# nrf7140_ml register map
Vendor: Nordic Semiconductor; Series: nRF71; File version: 1
Registers are 32-bit, read-write, reset 0x0 unless marked. A register's access mark holds for its fields unless they carry their own. Offsets are from the block's base; [hi:lo] are bit positions; lines under a group give offsets from that group; {n}, {i} and the like mark numbered series.

## GLOBAL_PCGCM300 — PCGC Master 0
Base 0x4900F000
Same registers: GLOBAL_PCGCM310 0x4901F000, PCGCM000 0x4A00F000, PCGCM010 0x4A01F000
{0xE0+4i} SETPWRCONTHRESHOLDBASE[{i}] (i=0..2) — Description collection: Set power consumption threshold base for power source / regulator n
  [3:0] SETPWRCONTHRESHOLDBASE
0xC00 UNLOCKBACKDOORS
  [15:0] UNLOCKBACKDOORS — Write: 0x00009375 to lock/unlock backdoors Read: 0x00000001 if backdoors is enabled Read: 0x00000000 if backdoors is disabled
0xC04 ENABLEPOWERREGFORCE
  [2:0] ENABLEPOWERREGFORCE
0xC08 POWERREGFORCE — Force reg
  [2:0] POWERREGFORCEREG
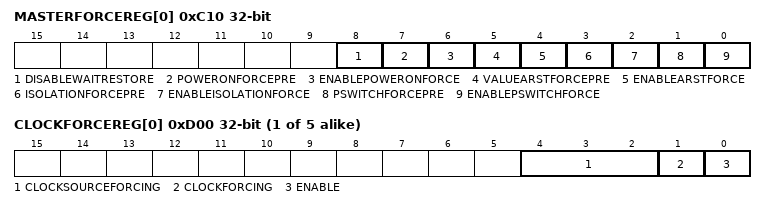
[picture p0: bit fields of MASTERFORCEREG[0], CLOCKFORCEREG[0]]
{0xC10+4i} MASTERFORCEREG[{i}] (i=0..0) — Description collection: Force reg
  [8] DISABLEWAITRESTORE — Turn off waiting for arst deactivation before retention restore
    1=Disable (Turn off waiting for arst deactivation before retention restore); 0=Enable (Wait for arst deactivation before retention restore)
  [7] POWERONFORCEPRE
  [6] ENABLEPOWERONFORCE
  [5] VALUEARSTFORCEPRE
  [4] ENABLEARSTFORCE
  [3] ISOLATIONFORCEPRE
  [2] ENABLEISOLATIONFORCE
  [1] PSWITCHFORCEPRE
  [0] ENABLEPSWITCHFORCE
{0xD00+4i} CLOCKFORCEREG[{i}] (i=0..4) — Description collection: Force clock n
  [4:2] CLOCKSOURCEFORCING
  [1] CLOCKFORCING
  [0] ENABLE — Enable clock forcing

## GLOBAL_MEMCONF310 — Memory configuration
Base 0x49011000
Same registers: MEMCONF 0x4A011000
{0x500+0x10*i} POWER[{i}] (i=0..1) group — Unspecified
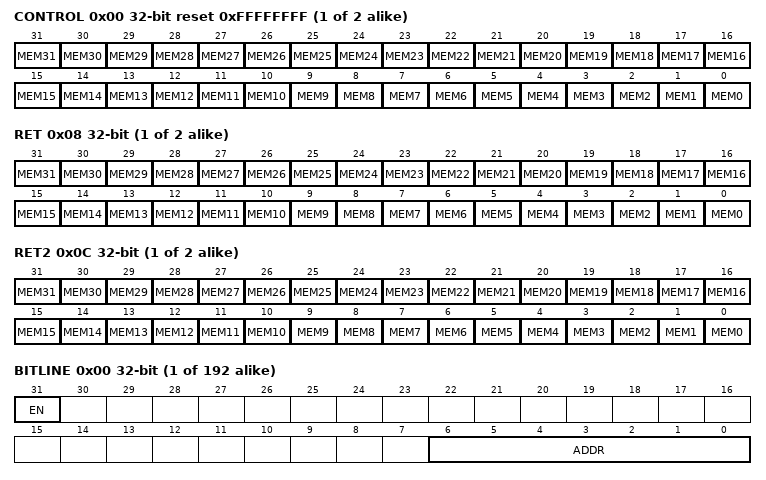
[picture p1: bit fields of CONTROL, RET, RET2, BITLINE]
  0x00 CONTROL reset 0xFFFFFFFF — Description cluster: Control memory block power.
    [all] fields
      0=Off (Power down); 1=On (Power up)
    [n] MEM{n} (n=0..31) — Keep the memory block MEM[{n}] on or off when in System ON mode.
  0x08 RET — Description cluster: RAM retention for RAM [n].
    [all] fields
      0=Off (Retention off); 1=On (Retention on)
    [n] MEM{n} (n=0..31) — Keep the RAM block MEM[{n}] retained when the parent power domain of the RAM is off.
  0x0C RET2 — Description cluster: RAM retention for the second bank in the RAM block
    [all] fields
      0=Off (Retention off); 1=On (Retention on)
    [n] MEM{n} (n=0..31) — Keep the second bank in RAM block MEM[{n}] retained when parent power domain of the RAM is off.
{0x600+4i} REPAIR[{i}] (i=0..191) group — Unspecified
  0x00 BITLINE — Description cluster: Repair configuration for RAM blocks.
    [31] EN — Enable bitline repair
      0=Disabled (Repair disabled.); 1=Enabled (Repair enabled.)
    [6:0] ADDR — Repair address of the bitline
{0x900+4i} BLOCKTYPE[{i}] (i=0..63) group — Unspecified
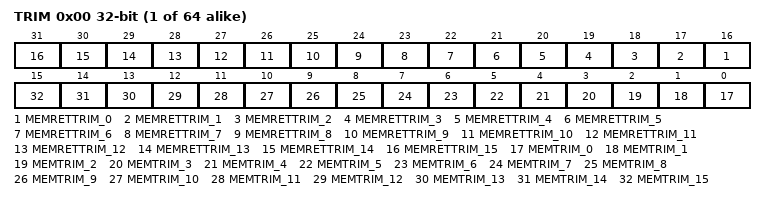
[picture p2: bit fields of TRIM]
  0x00 TRIM — Description cluster: Trim configuration for the memory block types.
    [n+16] MEMRETTRIM_{n} (n=0..15) — Trimming for retention mode for decreased leakage. Must be kept active in RAM retention mode.
    [n] MEMTRIM_{n} (n=0..15) — Read/write margin trim.

## BELLBOARD — BELLBOARD APB registers
Base 0x4F09D000
{0x0+4i} TASKS_TRIGGER[{i}] (i=0..31) wo — Description collection: Task TRIGGER[n]
  [0] TASKS_TRIGGER — Task TRIGGER[n]
    1=Trigger task
{0x100+4i} EVENTS_TRIGGERED[{i}] (i=0..31) — Description collection: Event TRIGGERED[n]
  [0] EVENTS_TRIGGERED — Event TRIGGERED[n]
    0=NotGenerated (Event not generated); 1=Generated (Event generated)
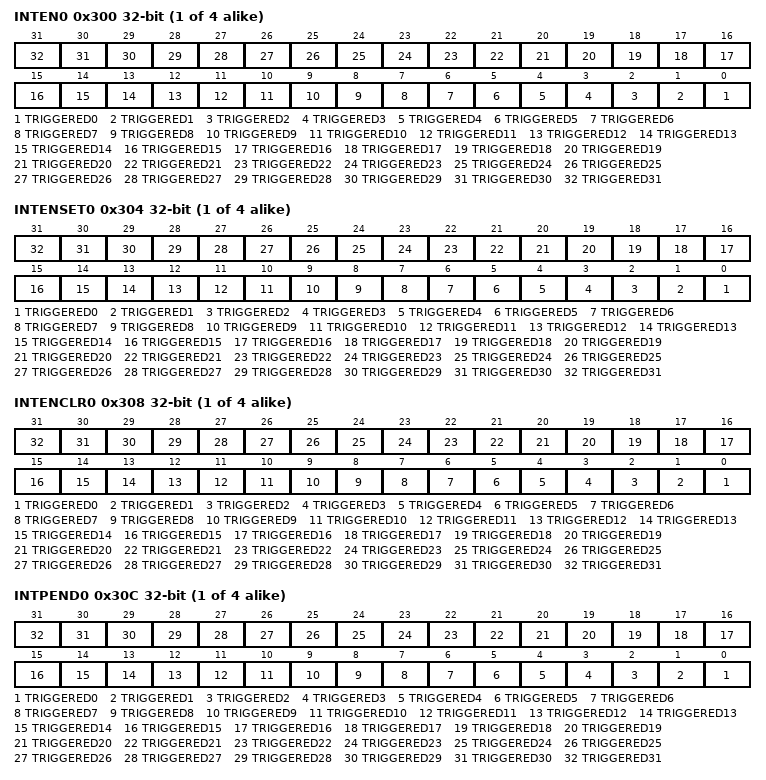
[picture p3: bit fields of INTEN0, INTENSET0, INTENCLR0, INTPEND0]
{0x300+0x10*i} INTEN{i} (i=0..3) — Enable or disable interrupt
  [all] fields
    0=Disabled; 1=Enabled
  [n] TRIGGERED{n} (n=0..31) — Enable or disable interrupt for event TRIGGERED[{n}]
{0x304+0x10*i} INTENSET{i} (i=0..3) — Enable interrupt
  [all] fields
    on read: 0=Disabled (Read: Disabled); 1=Enabled (Read: Enabled) | on write: 1=Set (Enable)
  [n] TRIGGERED{n} (n=0..31) — Write '1' to enable interrupt for event TRIGGERED[{n}]
{0x308+0x10*i} INTENCLR{i} (i=0..3) — Disable interrupt
  [all] fields
    on read: 0=Disabled (Read: Disabled); 1=Enabled (Read: Enabled) | on write: 1=Clear (Disable)
  [n] TRIGGERED{n} (n=0..31) — Write '1' to disable interrupt for event TRIGGERED[{n}]
{0x30C+0x10*i} INTPEND{i} ro (i=0..3) — Pending interrupts
  [all] fields
    on read: 0=NotPending (Read: Not pending); 1=Pending (Read: Pending)
  [n] TRIGGERED{n} (n=0..31) — Read pending status of interrupt for event TRIGGERED[{n}]
